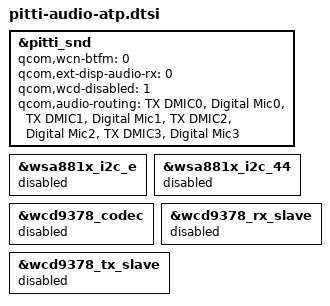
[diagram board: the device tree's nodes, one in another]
#include "pitti-audio-overlay.dtsi"

&pitti_snd {
	qcom,wcn-btfm = <0>;
	qcom,ext-disp-audio-rx = <0>;
	qcom,wcd-disabled =<1>;
	qcom,audio-routing =
		"TX DMIC0", "Digital Mic0",
		"TX DMIC1", "Digital Mic1",
		"TX DMIC2", "Digital Mic2",
		"TX DMIC3", "Digital Mic3";
};

&wsa881x_i2c_e {
	status = "disabled";
};

&wsa881x_i2c_44 {
	status = "disabled";
};

&wcd9378_codec {
	status = "disabled";
};

&wcd9378_rx_slave {
	status = "disabled";
};

&wcd9378_tx_slave {
	status = "disabled";
};
